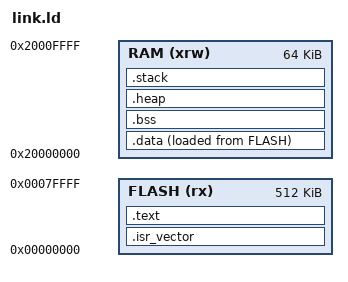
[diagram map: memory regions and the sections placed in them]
MEMORY
{
  FLASH (rx) : ORIGIN = 0x00000000, LENGTH = 512K
  RAM (xrw)  : ORIGIN = 0x20000000, LENGTH = 64K
  /* CODE_RAM (rwx) : ORIGIN = 0x800000, LENGTH = 0x10000*/
}




OUTPUT_FORMAT("elf32-littlearm", "elf32-littlearm", "elf32-littlearm")
OUTPUT_ARCH(arm)

/*ENTRY(Reset_Handler) /*int_vector*/
ENTRY(_start)
/*
 * Default stack sizes.
 * These are used by the startup in order to allocate stacks
 * for the different modes.
 */

__Main_Stack_Size = 1024 ;
__Heap_Size = 1024 ;

/* Populate information about ram size */
_sram = ORIGIN(RAM);
_eram = ORIGIN(RAM) + LENGTH(RAM);

/* Section Definitions */
SECTIONS
{
  /*
     * For Cortex-M devices, the beginning of the startup code is stored in
     * the .isr_vector section, which goes to FLASH.
     */
    .isr_vector : ALIGN(4)
    {
        FILL(0xFF)

        __vectors_start = ABSOLUTE(.) ;
        __vectors_start__ = ABSOLUTE(.) ; /* STM specific definition */
        KEEP(*(.isr_vector))     	/* Interrupt vectors */

        /*
          * This section is here for convenience, to store the
          * startup code at the beginning of the flash area, hoping that
          * this will increase the readability of the listing.
          */
        *(.after_vectors .after_vectors.*)	/* Startup code and ISR */

        KEEP(*(.eh_frame*))

        /*
		 * Stub sections generated by the linker, to glue together
		 * ARM and Thumb code. .glue_7 is used for ARM code calling
		 * Thumb code, and .glue_7t is used for Thumb code calling
		 * ARM code. Apparently always generated by the linker, for some
		 * architectures, so better leave them here.
		 */
        *(.glue_7)
        *(.glue_7t)

    } >FLASH

    /*
     * The program code is stored in the .text section,
     * which goes to FLASH.
     */
    .text : ALIGN(4)
    {
        _stext = .;
        *(.text .text.*)			/* all remaining code */

 		    /* read-only data (constants) */
        *(.rodata .rodata.* .constdata .constdata.*)

        . = ALIGN(4);
        _etext = .;

    } >FLASH

	/*
     * This address is used by the startup code to
     * initialise the .data section.
     */
    _sidata = LOADADDR(.data);
    /*
     * The initialised data section.
     *
     * The program executes knowing that the data is in the RAM
     * but the loader puts the initial values in the FLASH (inidata).
     * It is one task of the startup to copy the initial values from
     * FLASH to RAM.
     */
    .data : ALIGN(4)
    {
        FILL(0xFF)
        /* This is used by the startup code to initialise the .data section */
        _sdata = . ;        	/* STM specific definition */
        *(.data_begin .data_begin.*)

        *(.data .data.*)

        *(.data_end .data_end.*)

        . = ALIGN(4);

	      /* This is used by the startup code to initialise the .data section */
        _edata = . ;        	/* STM specific definition */

    } >RAM AT>FLASH

    /*
     * The uninitialised data sections. NOLOAD is used to avoid
     * the "section `.bss' type changed to PROGBITS" warning
     */
    /* .bss section which is used for uninitialized data */
    .bss (NOLOAD) :
    {
        . = ALIGN(4);
        _sbss = .;
        *(.bss .bss.*)
        *(COMMON)
        . = ALIGN(4);
        _ebss = .;
    } > RAM

    .heap (COPY):
    {
        __HeapBase = .;
        _Heap_Begin = __HeapBase;
        KEEP(*(.heap*))
        . = . + __Heap_Size;
        __HeapLimit = .;
        _Heap_Limit = __HeapLimit ;
    } > RAM



    /*.data :
    {
        *(.data*);
    } > RAM AT >FLASH*/

    /* stack section */

    .stack (NOLOAD):
    {
        . = ALIGN(8);
        __StackLimit = .;
        /*_sstack = .;*/
        . = . + __Main_Stack_Size;
        . = ALIGN(8);
        __StackTop = .;
        /*_estack = .;
        __StackTop = _estack;
        __stack = _estack;*/
      /* Check if data + heap + stack exceeds RAM limit */
      /*ASSERT(__StackLimit >= __HeapLimit, "region RAM overflowed");*/

    } > RAM



    /*_end = . ;*/

    /*.noinit (NOLOAD) : ALIGN(4)
    {
        _noinit = .;

        *(.noinit .noinit.*)

         . = ALIGN(4) ;
        _end_noinit = .;
    } > RAM*/

    /* Mandatory to be word aligned, _sbrk assumes this */
    /*PROVIDE ( end = _end_noinit );
    PROVIDE ( _end = _end_noinit );
    PROVIDE ( __end = _end_noinit );
    PROVIDE ( __end__ = _end_noinit );*/

    /* Set stack top to end of RAM, and stack limit move down by
	 * size of stack_dummy section */

/* Check if text sections + data exceeds FLASH limit */
    DataInitFlashUsed = _sbss - _sdata;
    CodeFlashUsed = _etext - ORIGIN(FLASH);
    TotalFlashUsed = CodeFlashUsed + DataInitFlashUsed;
    ASSERT(TotalFlashUsed <= LENGTH(FLASH), "region FLASH overflowed with .data and user data")
}
